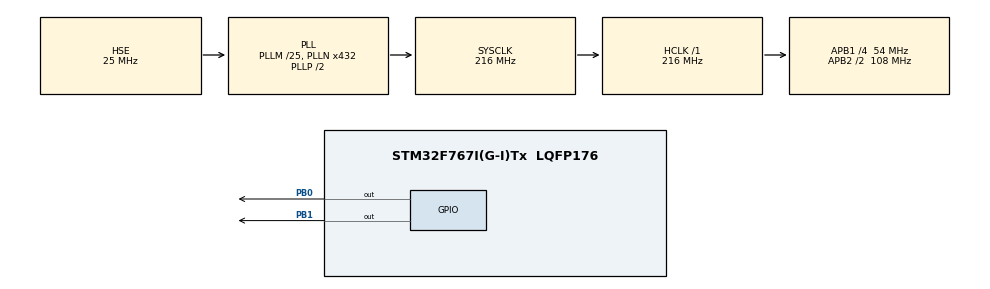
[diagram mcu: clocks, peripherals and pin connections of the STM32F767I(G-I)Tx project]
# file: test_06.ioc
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CORTEX_M7.default_mode_Activation=1
Mcu.Family=STM32F7
Mcu.Name=STM32F767I(G-I)Tx
Mcu.Package=LQFP176
NVIC.PriorityGroup=NVIC_PRIORITYGROUP_2
NVIC.WWDG_IRQn=true\:2\:3\:true\:false\:true\:true\:true\:true
PB0.GPIO_ModeDefaultOutputPP=GPIO_MODE_OUTPUT_PP
PB0.GPIO_PuPd=GPIO_PULLUP
PB0.GPIO_Speed=GPIO_SPEED_FREQ_HIGH
PB0.PinState=GPIO_PIN_SET
PB0.Signal=GPIO_Output
PB1.GPIO_ModeDefaultOutputPP=GPIO_MODE_OUTPUT_PP
PB1.GPIO_PuPd=GPIO_PULLUP
PB1.GPIO_Speed=GPIO_SPEED_FREQ_HIGH
PB1.PinState=GPIO_PIN_SET
PB1.Signal=GPIO_Output
PH0/OSC_IN.Mode=HSE-External-Oscillator
PH0/OSC_IN.Signal=RCC_OSC_IN
PH1/OSC_OUT.Mode=HSE-External-Oscillator
PH1/OSC_OUT.Signal=RCC_OSC_OUT
ProjectManager.HeapSize=0x200
ProjectManager.StackSize=0x400
ProjectManager.TargetToolchain=MDK-ARM V5.32
RCC.AHBFreq_Value=216000000
RCC.APB1CLKDivider=RCC_HCLK_DIV4
RCC.APB1Freq_Value=54000000
RCC.APB1TimFreq_Value=108000000
RCC.APB2CLKDivider=RCC_HCLK_DIV2
RCC.APB2Freq_Value=108000000
RCC.APB2TimFreq_Value=216000000
RCC.CortexFreq_Value=216000000
RCC.HCLKFreq_Value=216000000
RCC.HSE_VALUE=25000000
RCC.HSI_VALUE=16000000
RCC.LSE_VALUE=32768
RCC.PLLM=25
RCC.PLLN=432
RCC.PLLSourceVirtual=RCC_PLLSOURCE_HSE
RCC.SYSCLKFreq_VALUE=216000000
RCC.SYSCLKSource=RCC_SYSCLKSOURCE_PLLCLK
RCC.USBFreq_Value=216000000
RCC.VCOOutputFreq_Value=432000000
VP_WWDG_VS_WWDG.Mode=WWDG_Activate
WWDG.Counter=0x7f
WWDG.EWIMode=WWDG_EWI_ENABLE
WWDG.Prescaler=WWDG_PRESCALER_8
WWDG.Window=0x5f
board=custom

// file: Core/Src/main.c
/* USER CODE BEGIN Header */
/**
  ******************************************************************************
  * @file           : main.c
  * @brief          : Main program body
  ******************************************************************************
  * @attention
  *
  * Copyright (c) 2022 STMicroelectronics.
  * All rights reserved.
  *
  * This software is licensed under terms that can be found in the LICENSE file
  * in the root directory of this software component.
  * If no LICENSE file comes with this software, it is provided AS-IS.
  *
  ******************************************************************************
  */
/* USER CODE END Header */
#include "main.h"
#include "wwdg.h"
#include "gpio.h"

void SystemClock_Config(void);
static void MPU_Config(void);

int main(void)
{

  /* MPU Configuration--------------------------------------------------------*/
  MPU_Config();

  /* MCU Configuration--------------------------------------------------------*/

  /* Reset of all peripherals, Initializes the Flash interface and the Systick. */
  HAL_Init();

  /* Configure the system clock */
  SystemClock_Config();

  /* Initialize all configured peripherals */
  MX_GPIO_Init();
  LED0(0);		//点亮LED0
  HAL_Delay(300);	//延时300ms，再初始化看门狗，LED0的变化可见
  MX_WWDG_Init();

  /* Infinite loop */
  /* USER CODE BEGIN WHILE */
  while (1)
  {
	  LED0(1);		//熄灭LED0
    /* USER CODE END WHILE */

  }
}

void SystemClock_Config(void)
{
  RCC_OscInitTypeDef RCC_OscInitStruct = {0};
  RCC_ClkInitTypeDef RCC_ClkInitStruct = {0};

  /** Configure the main internal regulator output voltage
  */
  __HAL_RCC_PWR_CLK_ENABLE();
  __HAL_PWR_VOLTAGESCALING_CONFIG(PWR_REGULATOR_VOLTAGE_SCALE1);

  /** Initializes the RCC Oscillators according to the specified parameters
  * in the RCC_OscInitTypeDef structure.
  */
  RCC_OscInitStruct.OscillatorType = RCC_OSCILLATORTYPE_HSE;
  RCC_OscInitStruct.HSEState = RCC_HSE_ON;
  RCC_OscInitStruct.PLL.PLLState = RCC_PLL_ON;
  RCC_OscInitStruct.PLL.PLLSource = RCC_PLLSOURCE_HSE;
  RCC_OscInitStruct.PLL.PLLM = 25;
  RCC_OscInitStruct.PLL.PLLN = 432;
  RCC_OscInitStruct.PLL.PLLP = RCC_PLLP_DIV2;
  RCC_OscInitStruct.PLL.PLLQ = 2;
  RCC_OscInitStruct.PLL.PLLR = 2;
  if (HAL_RCC_OscConfig(&RCC_OscInitStruct) != HAL_OK)
  {
    Error_Handler();
  }

  /** Activate the Over-Drive mode
  */
  if (HAL_PWREx_EnableOverDrive() != HAL_OK)
  {
    Error_Handler();
  }

  /** Initializes the CPU, AHB and APB buses clocks
  */
  RCC_ClkInitStruct.ClockType = RCC_CLOCKTYPE_HCLK|RCC_CLOCKTYPE_SYSCLK
                              |RCC_CLOCKTYPE_PCLK1|RCC_CLOCKTYPE_PCLK2;
  RCC_ClkInitStruct.SYSCLKSource = RCC_SYSCLKSOURCE_PLLCLK;
  RCC_ClkInitStruct.AHBCLKDivider = RCC_SYSCLK_DIV1;
  RCC_ClkInitStruct.APB1CLKDivider = RCC_HCLK_DIV4;
  RCC_ClkInitStruct.APB2CLKDivider = RCC_HCLK_DIV2;

  if (HAL_RCC_ClockConfig(&RCC_ClkInitStruct, FLASH_LATENCY_7) != HAL_OK)
  {
    Error_Handler();
  }
}

/* MPU Configuration */

void MPU_Config(void)
{
  MPU_Region_InitTypeDef MPU_InitStruct = {0};

  /* Disables the MPU */
  HAL_MPU_Disable();

  /** Initializes and configures the Region and the memory to be protected
  */
  MPU_InitStruct.Enable = MPU_REGION_ENABLE;
  MPU_InitStruct.Number = MPU_REGION_NUMBER0;
  MPU_InitStruct.BaseAddress = 0x0;
  MPU_InitStruct.Size = MPU_REGION_SIZE_4GB;
  MPU_InitStruct.SubRegionDisable = 0x87;
  MPU_InitStruct.TypeExtField = MPU_TEX_LEVEL0;
  MPU_InitStruct.AccessPermission = MPU_REGION_NO_ACCESS;
  MPU_InitStruct.DisableExec = MPU_INSTRUCTION_ACCESS_DISABLE;
  MPU_InitStruct.IsShareable = MPU_ACCESS_SHAREABLE;
  MPU_InitStruct.IsCacheable = MPU_ACCESS_NOT_CACHEABLE;
  MPU_InitStruct.IsBufferable = MPU_ACCESS_NOT_BUFFERABLE;

  HAL_MPU_ConfigRegion(&MPU_InitStruct);
  /* Enables the MPU */
  HAL_MPU_Enable(MPU_PRIVILEGED_DEFAULT);

}

void Error_Handler(void)
{
  __disable_irq();
  while (1)
  {
  }
}
